# systick register map
Vendor: Texas Instruments
Peripheral module from a debugger description file (folder MSP432).
Registers are 32-bit, read-write, no defined reset value unless marked. A register's access mark holds for its fields unless they carry their own. Offsets are as the file gives them; lines under a group give offsets from that group; [hi:lo] are bit positions; {n}, {i} and the like mark numbered series; 'fields as' and 'values as' point back to an identical list; <NAME> marks a mode.

## SYSTICK
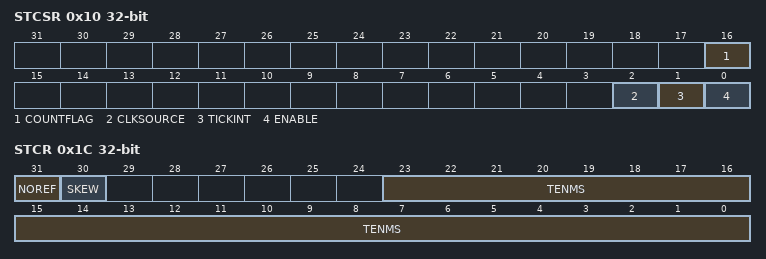
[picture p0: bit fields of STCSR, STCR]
0x10 STCSR — SysTick Control and Status Register
  [16] COUNTFLAG — Returns 1 if timer counted to 0 since last time this was read
  [2] CLKSOURCE — Clock source
    0=CLKSOURCE__0 (External reference clock.); 1=CLKSOURCE__1 (Core clock.)
  [1] TICKINT
    0=TICKINT__0 (Counting down to zero does not pend the SysTick handler); 1=TICKINT__1 (Counting down to zero pends the SysTick handler.)
  [0] ENABLE — Enable SysTick counter
    0=ENABLE__0 (Counter disabled)
0x14 STRVR — SysTick Reload Value Register
  [23:0] RELOAD — Value to load into the SysTick Current Value Register when the
0x18 STCVR — SysTick Current Value Register
  [23:0] CURRENT — Current value at the time the register is accessed
0x1C STCR — SysTick Calibration Value Register
  [31] NOREF — Reads as one
  [30] SKEW — Reads as one
  [23:0] TENMS — Reads as zero. Indicates calibration value is not known.
